AUTOSAR XML (schema 314)
package /ComponentType
  internal behavior Sa_HwTqArbn_InternalBehavior: component=Sa_HwTqArbn
    4 x timing event:
      HwTqArbn_Init1_InitEvent: start-on-event=HwTqArbn_Init1, period=0
      TMT_HwTqArbn_Per1: start-on-event=HwTqArbn_Per1, period=0.002
      TMT_HwTqArbn_Per2: start-on-event=HwTqArbn_Per2, period=0.002
      TMT_HwTqArbn_Per3: start-on-event=HwTqArbn_Per3, period=0.1
    4 x operation invoked event:
      OIT_HwTrqArbn_SCom_ClrHwTrqArbOffsetTrim_HwTrqArbn_SCom_ClrHwTrqArbOffsetTrim: start-on-event=HwTrqArbn_SCom_ClrHwTrqArbOffsetTrim, operation=HwTrqArbn_SCom.ClrHwTrqArbOffsetTrim
      OIT_HwTrqArbn_SCom_ReadHwTrqArbOffsetTrim_HwTrqArbn_SCom_ReadHwTrqArbOffsetTrim: start-on-event=HwTrqArbn_SCom_ReadHwTrqArbOffsetTrim, operation=HwTrqArbn_SCom.ReadHwTrqArbOffsetTrim
      OIT_HwTrqArbn_SCom_SetHwTrqArbOffsetTrim_HwTrqArbn_SCom_SetHwTrqArbOffsetTrim: start-on-event=HwTrqArbn_SCom_SetHwTrqArbOffsetTrim, operation=HwTrqArbn_SCom.SetHwTrqArbOffsetTrim
      OIT_HwTrqArbn_SCom_WriteHwTrqArbOffsetTrim_HwTrqArbn_SCom_WriteHwTrqArbOffsetTrim: start-on-event=HwTrqArbn_SCom_WriteHwTrqArbOffsetTrim, operation=HwTrqArbn_SCom.WriteHwTrqArbOffsetTrim
    per instance memory HwTqArbnEOLCh1OffsetTrimData: type=EOLChOffsetTrim_DataType, type-definition=/DataType/EOLChOffsetTrim_DataType
    port-api-options:
      enable-take-address=false, indirect-api=false, port=HwTq1Qlfr
      enable-take-address=false, indirect-api=false, port=HwTq1RollgCntr
      enable-take-address=false, indirect-api=false, port=HwTq1Val
      enable-take-address=false, indirect-api=false, port=HwTq2Qlfr
      enable-take-address=false, indirect-api=false, port=HwTq2RollgCntr
      enable-take-address=false, indirect-api=false, port=HwTq2Val
      enable-take-address=false, indirect-api=false, port=HwTqArbnEOLCh1OffsetTrim
      enable-take-address=false, indirect-api=false, port=HwTqCorrlnSts
      enable-take-address=false, indirect-api=false, port=HwTqVal
      enable-take-address=false, indirect-api=false, port=HwTrqArbn_SCom
      enable-take-address=false, indirect-api=false, port=MEC_Counter
      enable-take-address=false, indirect-api=false, port=NxtrDiagMgr
      enable-take-address=false, indirect-api=false, port=SVC_ClearCodes
    8 x runnable:
      HwTqArbn_Init1
      HwTqArbn_Per1: minimum-start-interval=0.002
        5 x data read access:
          READ_HwTq1Qlfr_State_enum: data-element=HwTq1Qlfr.State_enum
          READ_HwTq1RollgCntr_Cnt_u08: data-element=HwTq1RollgCntr.Cnt_u08
          READ_HwTq2Qlfr_State_enum: data-element=HwTq2Qlfr.State_enum
          READ_HwTq2RollgCntr_Cnt_u08: data-element=HwTq2RollgCntr.Cnt_u08
          READ_HwTqCorrlnSts_Cnt_u16: data-element=HwTqCorrlnSts.Cnt_u16
      HwTqArbn_Per2
        data read access READ_HwTq1Val_HwNm_f32: data-element=HwTq1Val.HwNm_f32
        data read access READ_HwTq2Val_HwNm_f32: data-element=HwTq2Val.HwNm_f32
        data write access WRITE_HwTqVal_HwNm_f32: data-element=HwTqVal.HwNm_f32
      HwTqArbn_Per3
        data read access READ_MEC_Counter_Cnt_u08: data-element=MEC_Counter.Cnt_u08
        data read access READ_SVC_ClearCodes_Cnt_lgc: data-element=SVC_ClearCodes.Cnt_lgc
        sync call SC_NxtrDiagMgr_SetNTCStatus: operation=NxtrDiagMgr.SetNTCStatus, timeout=0
      HwTrqArbn_SCom_ClrHwTrqArbOffsetTrim
        sync call SC_HwTqArbnEOLCh1OffsetTrim_WriteBlock: operation=HwTqArbnEOLCh1OffsetTrim.WriteBlock, timeout=0
      HwTrqArbn_SCom_ReadHwTrqArbOffsetTrim
      HwTrqArbn_SCom_SetHwTrqArbOffsetTrim
        sync call SC_HwTqArbnEOLCh1OffsetTrim_WriteBlock: operation=HwTqArbnEOLCh1OffsetTrim.WriteBlock, timeout=0
      HwTrqArbn_SCom_WriteHwTrqArbOffsetTrim
        sync call SC_HwTqArbnEOLCh1OffsetTrim_WriteBlock: operation=HwTqArbnEOLCh1OffsetTrim.WriteBlock, timeout=0
    service-needss:
      swc nv block needs HwTqArbnEOLCh1OffsetTrimBlk: n-data-sets=0, readonly=false, reliability=LOW, resistant-to-changed-sw=false, restore-at-start=false, write-only-once=false, writing-frequency=0, writing-priority=LOW, mirror-block=HwTqArbnEOLCh1OffsetTrimData
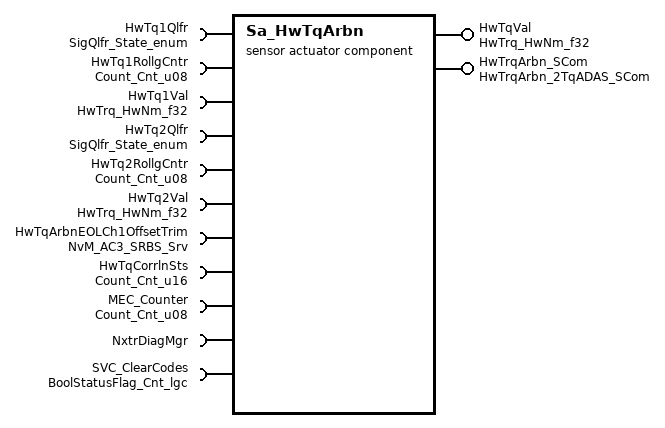
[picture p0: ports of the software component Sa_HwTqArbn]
  sensor actuator software component type Sa_HwTqArbn
    provide port HwTqVal: unqueued-sender-com-spec{data-element=HwNm_f32, can-invalidate=false, init-value=D_ZERO_ULS_F32}, provided-interface=HwTrq_HwNm_f32
    provide port HwTrqArbn_SCom: provided-interface=HwTrqArbn_2TqADAS_SCom
      provided-com-specs:
        operation=ClrHwTrqArbOffsetTrim, queue-length=1
        operation=ReadHwTrqArbOffsetTrim, queue-length=1
        operation=SetHwTrqArbOffsetTrim, queue-length=1
        operation=WriteHwTrqArbOffsetTrim, queue-length=1
    11 x require port:
      HwTq1Qlfr: unqueued-receiver-com-spec{data-element=State_enum, init-value=D_SIGQLFRNORES_CNT_ENUM}, required-interface=SigQlfr_State_enum
      HwTq1RollgCntr: unqueued-receiver-com-spec{data-element=Cnt_u08, init-value=D_ZERO_CNT_U8}, required-interface=Count_Cnt_u08
      HwTq1Val: unqueued-receiver-com-spec{data-element=HwNm_f32, init-value=D_ZERO_ULS_F32}, required-interface=HwTrq_HwNm_f32
      HwTq2Qlfr: unqueued-receiver-com-spec{data-element=State_enum, init-value=D_SIGQLFRNORES_CNT_ENUM}, required-interface=SigQlfr_State_enum
      HwTq2RollgCntr: unqueued-receiver-com-spec{data-element=Cnt_u08, init-value=D_ZERO_CNT_U8}, required-interface=Count_Cnt_u08
      HwTq2Val: unqueued-receiver-com-spec{data-element=HwNm_f32, init-value=D_ZERO_ULS_F32}, required-interface=HwTrq_HwNm_f32
      HwTqArbnEOLCh1OffsetTrim: required-com-specs=[EraseBlock, GetErrorStatus, InvalidateNvBlock, ReadBlock, SetRamBlockStatus, WriteBlock], required-interface=NvM_AC3_SRBS_Srv
      HwTqCorrlnSts: unqueued-receiver-com-spec{data-element=Cnt_u16, init-value=D_THREE_CNT_U16}, required-interface=Count_Cnt_u16
      MEC_Counter: unqueued-receiver-com-spec{data-element=Cnt_u08, init-value=D_ZERO_CNT_U8}, required-interface=Count_Cnt_u08
      NxtrDiagMgr: required-com-specs=[GetNTCActive, GetNTCFailed, GetNTCStatus, SetNTCStatus], required-interface=NxtrDiagMgr
      SVC_ClearCodes: unqueued-receiver-com-spec{data-element=Cnt_lgc, init-value=D_FALSE_CNT_LGC}, required-interface=BoolStatusFlag_Cnt_lgc
  swc implementation Sa_HwTqArbn_Implementation: behavior=Sa_HwTqArbn_InternalBehavior
    code-descriptors:
      code Code: type=SRC
